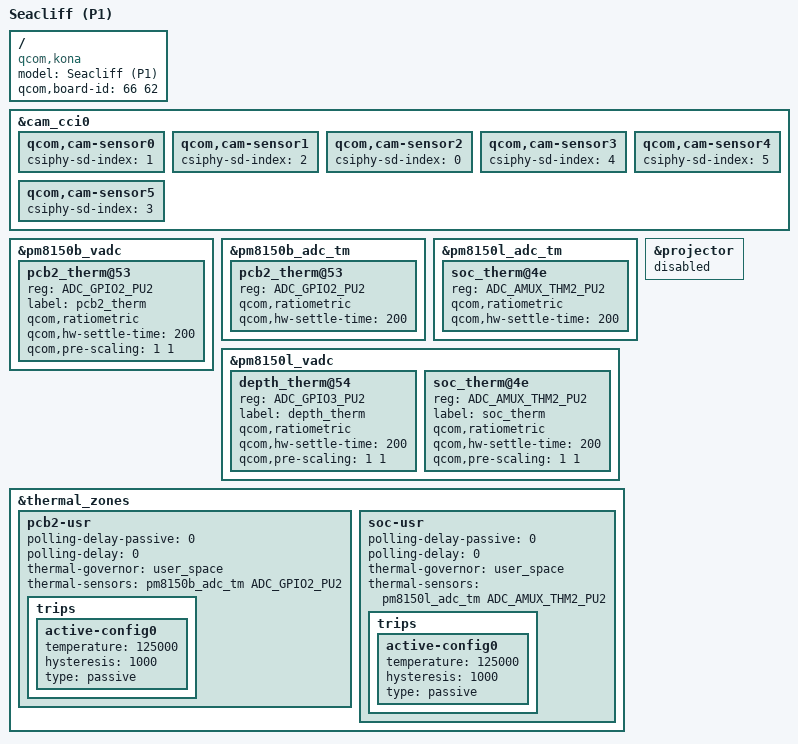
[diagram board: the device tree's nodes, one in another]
/dts-v1/;
/plugin/;

#include <dt-bindings/clock/qcom,gcc-kona.h>
#include <dt-bindings/clock/qcom,camcc-kona.h>
#include <dt-bindings/clock/qcom,rpmh.h>
#include <dt-bindings/interrupt-controller/arm-gic.h>

#include "seacliff-pop.dtsi"
#include "seacliff-bcmdhd.dtsi"

/ {
	model = "Seacliff (P1)";
	compatible = "qcom,kona";
	qcom,board-id = <66 62>;
};

&cam_cci0 {
	qcom,cam-sensor0 {
		csiphy-sd-index = <1>;
	};
	qcom,cam-sensor1 {
		csiphy-sd-index = <2>;
	};
	qcom,cam-sensor2 {
		csiphy-sd-index = <0>;
	};
	qcom,cam-sensor3 {
		csiphy-sd-index = <4>;
	};
	qcom,cam-sensor4 {
		csiphy-sd-index = <5>;
	};
	qcom,cam-sensor5 {
		csiphy-sd-index = <3>;
	};
};

&pm8150b_vadc {
	pcb2_therm@53 {
		reg = <ADC_GPIO2_PU2>;
		label = "pcb2_therm";
		qcom,ratiometric;
		qcom,hw-settle-time = <200>;
		qcom,pre-scaling = <1 1>;
	};
};

&pm8150b_adc_tm {
	pcb2_therm@53 {
		reg = <ADC_GPIO2_PU2>;
		qcom,ratiometric;
		qcom,hw-settle-time = <200>;
	};
};

&pm8150l_adc_tm {
	soc_therm@4e {
		reg = <ADC_AMUX_THM2_PU2>;
		qcom,ratiometric;
		qcom,hw-settle-time = <200>;
	};
};

&pm8150l_vadc {
	depth_therm@54 {
		reg = <ADC_GPIO3_PU2>;
		label = "depth_therm";
		qcom,ratiometric;
		qcom,hw-settle-time = <200>;
		qcom,pre-scaling = <1 1>;
	};

	soc_therm@4e {
		reg = <ADC_AMUX_THM2_PU2>;
		label = "soc_therm";
		qcom,ratiometric;
		qcom,hw-settle-time = <200>;
		qcom,pre-scaling = <1 1>;
	};
};

&thermal_zones {
	pcb2-usr {
		polling-delay-passive = <0>;
		polling-delay = <0>;
		thermal-governor = "user_space";
		thermal-sensors = <&pm8150b_adc_tm ADC_GPIO2_PU2>;
		trips {
			active-config0 {
				temperature = <125000>;
				hysteresis = <1000>;
				type = "passive";
			};
		};
	};

	soc-usr {
		polling-delay-passive = <0>;
		polling-delay = <0>;
		thermal-governor = "user_space";
		thermal-sensors = <&pm8150l_adc_tm ADC_AMUX_THM2_PU2>;
		trips {
			active-config0 {
				temperature = <125000>;
				hysteresis = <1000>;
				type = "passive";
			};
		};
	};
};

&projector {
	status = "disabled";
};
